AUTOSAR XML (schema 00046)
package /ComponentTypes
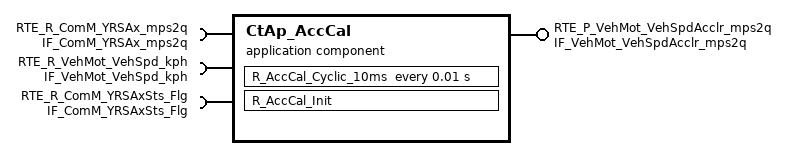
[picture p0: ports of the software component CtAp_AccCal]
  application sw component type CtAp_AccCal
    provide port RTE_P_VehMot_VehSpdAcclr_mps2q: nonqueued-sender-com-spec{data-element=tec_VehMot_VehSpdAcclr_mps2q, init-value=0}, provided-interface=IF_VehMot_VehSpdAcclr_mps2q
    require port RTE_R_ComM_YRSAx_mps2q: nonqueued-receiver-com-spec{data-element=tec_ComM_YRSAx_mps2q, filter=data-filter-type=ALWAYS, init-value=0}, required-interface=IF_ComM_YRSAx_mps2q
    require port RTE_R_VehMot_VehSpd_kph: nonqueued-receiver-com-spec{data-element=tec_VehMot_VehSpd_kph, filter=data-filter-type=ALWAYS, init-value=0}, required-interface=IF_VehMot_VehSpd_kph
    require port RTE_R_ComM_YRSAxSts_Flg: nonqueued-receiver-com-spec{data-element=tec_ComM_YRSAxSts_Flg, filter=data-filter-type=ALWAYS, init-value=0}, required-interface=IF_ComM_YRSAxSts_Flg
    behavior CtAp_AccCal_InternalBehavior
      init event CtAp_AccCal_InitEvent: start-on-event=R_AccCal_Init
      timing event TMT_R_AccCal_Cyclic_10ms: start-on-event=R_AccCal_Cyclic_10ms, period=0.01
      runnable R_AccCal_Init
      runnable R_AccCal_Cyclic_10ms
        data-receive-point-by-arguments:
          access REC_RTE_R_ComM_YRSAx_mps2q_tec_ComM_YRSAx_mps2q: accessed-variable=RTE_R_ComM_YRSAx_mps2q.tec_ComM_YRSAx_mps2q
          access REC_RTE_R_VehMot_VehSpd_kph_tec_VehMot_VehSpd_kph: accessed-variable=RTE_R_VehMot_VehSpd_kph.tec_VehMot_VehSpd_kph
          access REC_RTE_R_ComM_YRSAxSts_Flg_tec_ComM_YRSAxSts_Flg: accessed-variable=RTE_R_ComM_YRSAxSts_Flg.tec_ComM_YRSAxSts_Flg
        data-send-points:
          access SEND_RTE_P_VehMot_VehSpdAcclr_mps2q_tec_VehMot_VehSpdAcclr_mps2q: accessed-variable=RTE_P_VehMot_VehSpdAcclr_mps2q.tec_VehMot_VehSpdAcclr_mps2q
  swc implementation CtAp_AccCal_Implementation: behavior=CtAp_AccCal_InternalBehavior
    code-descriptors:
      code Default: artifact-descriptors=autosar-engineering-object=category=SWOBJ
